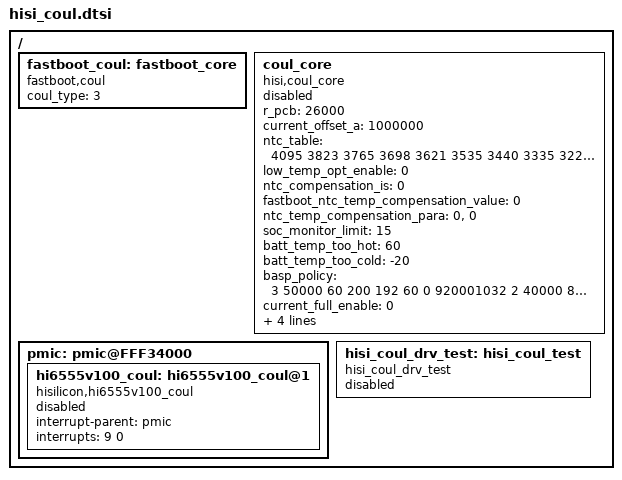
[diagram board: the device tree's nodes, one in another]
 / {
    fastboot_coul:fastboot_core {
        compatible = "fastboot,coul";
        coul_type = <3>; /*hi6555v100*/
        status = "ok";
    };

    coul_core:coul_core{
        compatible = "hisi,coul_core";
        r_pcb = <26000>;
        current_offset_a = <1000000>;
       /*ntc_temp = <-273 -40  -36  -32  -28  -24  -20  -16  -12  -8   -4   0    4    8    12   16   20   24   28   32   36   40   44   48   52   56   60   64   74   84   125  0>*/
        ntc_table = <4095 3823 3765 3698 3621 3535 3440 3335 3223 3104 2979 2851 2721 2591 2464 2339 2219 2106 1999 1899 1807 1722 1645 1575 1511 1454 1403 1357 1262 1190 1038 0>;
        low_temp_opt_enable = <0>;
        ntc_compensation_is = <0>;
        fastboot_ntc_temp_compensation_value = <0>;
        ntc_temp_compensation_para =
                  "0", "0";
        soc_monitor_limit = <15>;
		batt_temp_too_hot = "60";
		batt_temp_too_cold = "-20";
		basp_policy = <
			3 50000 60  200 192 60  0 920001032
			2 40000 80  40  48  80  0 920001031
			1 30000 90  20  16  90  0 920001029
			0 0     0   0   0   100 0 0
		>;
		current_full_enable = <0>;
		multi_ocv_open = <1>;
		fcc_update_limit = <1>;
	    normal_cutoff_vol_mv = <3150>;
	    sleep_cutoff_vol_mv = <3350>;
	    status = "disabled";
   };
   pmic: pmic@FFF34000 {  
        hi6555v100_coul: hi6555v100_coul@1 {
              compatible = "hisilicon,hi6555v100_coul";
	          interrupt-parent = <&pmic>;
              interrupts = <9 0>;
              interrupt-names = "coulirq";						
	          status = "disabled";
        };
   };
   hisi_coul_drv_test:hisi_coul_test {
   	    compatible = "hisi_coul_drv_test";
	    status = "disabled";
   };
	
};
